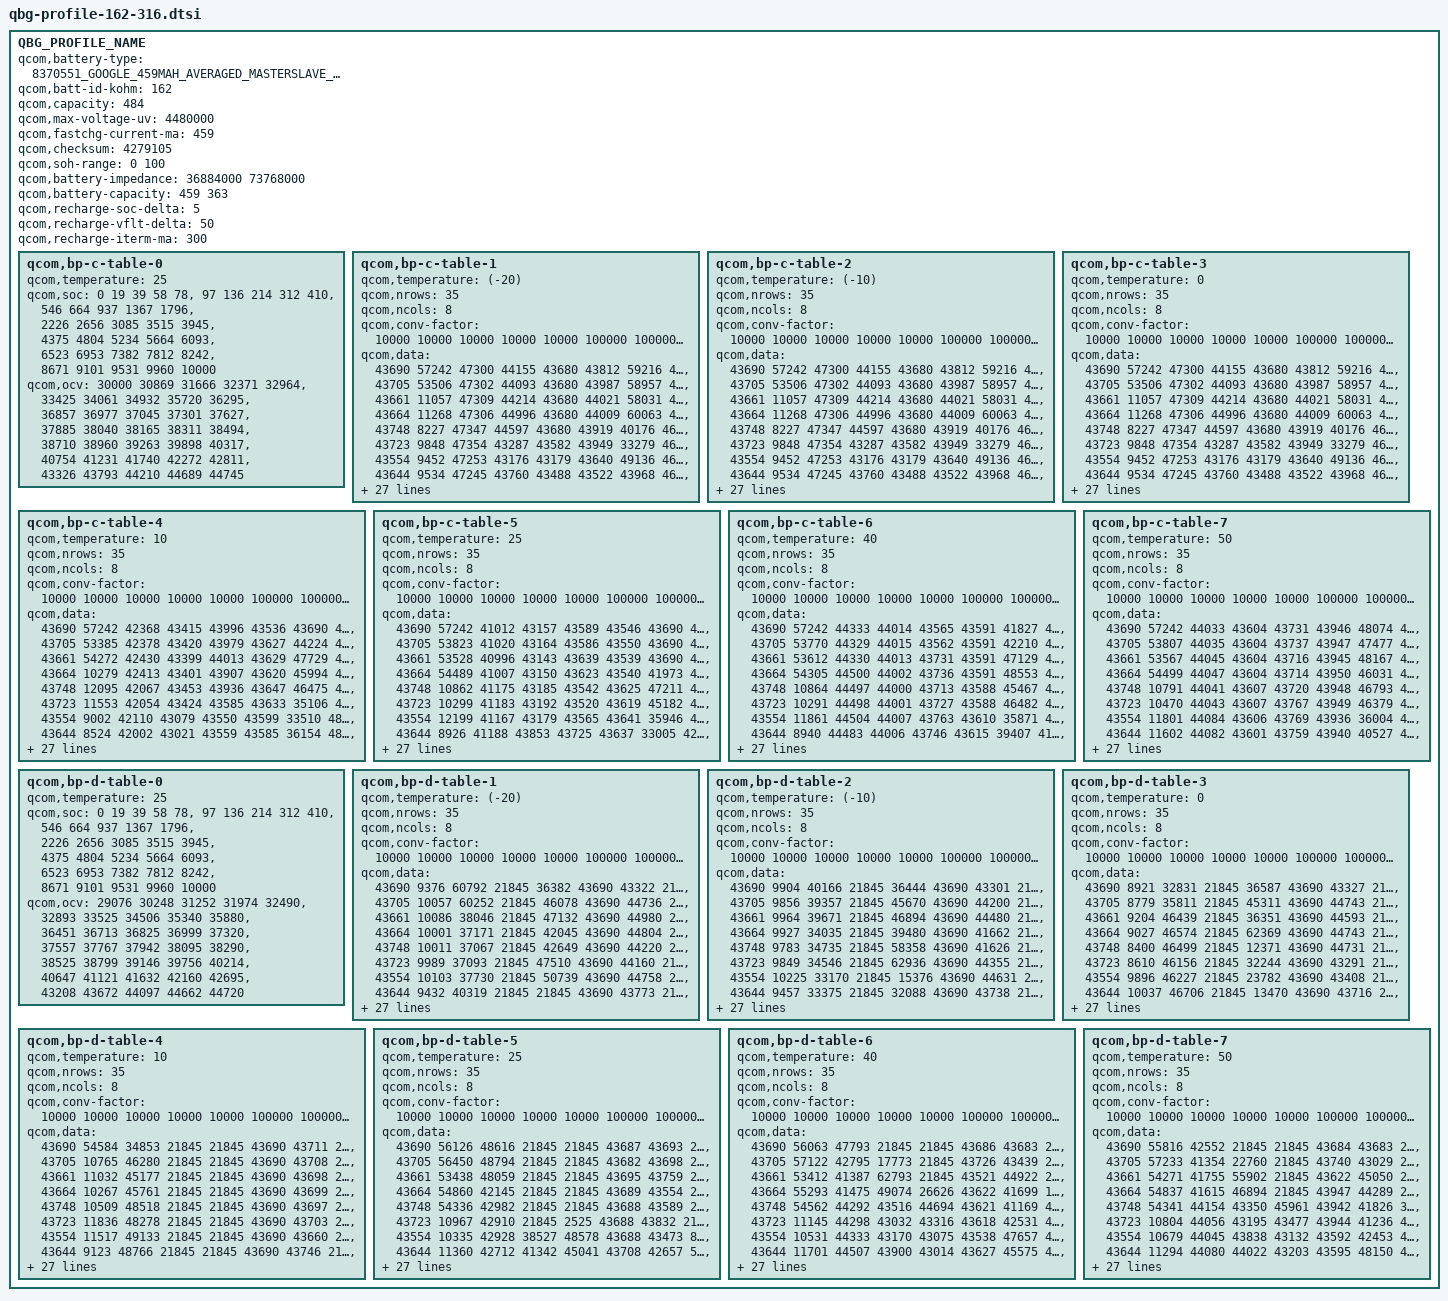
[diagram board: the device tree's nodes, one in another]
/*QBG Profiling Rev. 2.8*/

QBG_PROFILE_NAME {
	qcom,battery-type = "8370551_GOOGLE_459MAH_AVERAGED_MASTERSLAVE_MAR6TH2026";
	qcom,batt-id-kohm = <162>;
	qcom,capacity = <484>;
	qcom,max-voltage-uv = <4480000>;
	qcom,fastchg-current-ma = <459>;
	qcom,checksum = <4279105>; /*@5, 0.005V, 4% */
	qcom,soh-range = <0 100>;
	qcom,battery-impedance = <36884000 73768000>; /*Nominal_Impedance in 10nohm @ SOC 50% 25C* 0:fresh cell, 1: aged cell*/
	qcom,battery-capacity = <459 363>; /*Nominal_Capacity in mAh. 0: fresh cell, 1:aged cell*/ 
	qcom,recharge-soc-delta =<5>; /*SOC delta (in percent) dropped from EOC SOC to enable recharge*/ 
	qcom,recharge-vflt-delta =<50>; /*vfloat delta (in mV) dropped from regular vfloat in recharge*/ 
	qcom,recharge-iterm-ma = <300>; /*termination current (in mA) in recharge*/ 

	qcom,bp-c-table-0 {
		qcom,temperature = <25>;
		qcom,soc = <    0    19    39    58    78>,
			<   97   136   214   312   410>,
			<  546   664   937  1367  1796>,
			< 2226  2656  3085  3515  3945>,
			< 4375  4804  5234  5664  6093>,
			< 6523  6953  7382  7812  8242>,
			< 8671  9101  9531  9960 10000>;
		qcom,ocv = <30000 30869 31666 32371 32964>,
			<33425 34061 34932 35720 36295>,
			<36857 36977 37045 37301 37627>,
			<37885 38040 38165 38311 38494>,
			<38710 38960 39263 39898 40317>,
			<40754 41231 41740 42272 42811>,
			<43326 43793 44210 44689 44745>;
	};
	qcom,bp-c-table-1 {
		qcom,temperature = <(-20)>;
		qcom,nrows = <35>;
		qcom,ncols = <8>;
		qcom,conv-factor = <10000 10000 10000 10000 10000 100000 100000 10000>;
		qcom,data = <43690 57242 47300 44155 43680 43812 59216 46344>,
			<43705 53506 47302 44093 43680 43987 58957 46532>,
			<43661 11057 47309 44214 43680 44021 58031 46493>,
			<43664 11268 47306 44996 43680 44009 60063 46507>,
			<43748  8227 47347 44597 43680 43919 40176 46176>,
			<43723  9848 47354 43287 43582 43949 33279 46142>,
			<43554  9452 47253 43176 43179 43640 49136 46232>,
			<43644  9534 47245 43760 43488 43522 43968 46850>,
			<43922 15072 47295 43664 43497 43625 44008 47096>,
			<43824 14882 47233 43666 43417 43622 44002 47039>,
			<43144 14959 47283 43758 43398 43619 43977 47017>,
			<43058 14929 47355 43772 43406 43625 43816 47013>,
			<43267 15121 47286 43765 43402 43625 43838 47019>,
			<45053 14726 47130 43052 43306 43543 44303 46422>,
			<44462 16010 47109 44221 43917 43624 32951 35351>,
			<41496 15972 47254 44069 43836 43542 35658 35397>,
			<41162 16285 47235 44101 43843 43536 46584 35740>,
			<42663 16139 47334 44443 43191 43548 46957 35704>,
			<42769 15491 47359 44502 43250 43547 45395 34831>,
			<42435 15457 47124 44360 43062 43521 47103 35094>,
			<48061 15645 47168 41604 43018 43535 46985 36565>,
			<47214 13225 47492 41725 43046 43572 45995 36788>,
			<48856 12332 47407 41505 43041 43583 47247 36001>,
			<48266 14014 47429 41551 43110 43553 42769 36155>,
			<48487 14106 48682 41958 43394 43560 41041 33742>,
			<46033 13771 49025 41834 43269 43728 41551 33079>,
			<45443  2946 48915 41117 44789 43742 44321 33972>,
			<46716  2467 48185 40995 44998 43736 44172 39866>,
			<46126  3671 48445 41033 44101 43736 44941 40552>,
			<35480  3158 45747 41357 41916 43742 44744 37867>,
			<35701   601 45786 41450 42699 43743 43319 37962>,
			<35111   110 46016 41392 47936 43743 43099 60512>,
			<36753  1734 46079 41792 45451 43718 43235 64340>,
			<35906  1203 45903 44637 49003 43751 43945 57741>,
			<36282  1258 45909 44774 48678 43747 43639 58124>;
	};
	qcom,bp-c-table-2 {
		qcom,temperature = <(-10)>;
		qcom,nrows = <35>;
		qcom,ncols = <8>;
		qcom,conv-factor = <10000 10000 10000 10000 10000 100000 100000 10000>;
		qcom,data = <43690 57242 47300 44155 43680 43812 59216 46344>,
			<43705 53506 47302 44093 43680 43987 58957 46532>,
			<43661 11057 47309 44214 43680 44021 58031 46493>,
			<43664 11268 47306 44996 43680 44009 60063 46507>,
			<43748  8227 47347 44597 43680 43919 40176 46176>,
			<43723  9848 47354 43287 43582 43949 33279 46142>,
			<43554  9452 47253 43176 43179 43640 49136 46232>,
			<43644  9534 47245 43760 43488 43522 43968 46850>,
			<43922 15072 47295 43664 43497 43625 44008 47096>,
			<43824 14882 47233 43666 43417 43622 44002 47039>,
			<43144 14959 47283 43758 43398 43619 43977 47017>,
			<43058 14929 47355 43772 43406 43625 43816 47013>,
			<43267 15121 47286 43765 43402 43625 43838 47019>,
			<45053 14726 47130 43052 43306 43543 44303 46422>,
			<44462 16010 47109 44221 43917 43624 32951 35351>,
			<41496 15972 47254 44069 43836 43542 35658 35397>,
			<41162 16285 47235 44101 43843 43536 46584 35740>,
			<42663 16139 47334 44443 43191 43548 46957 35704>,
			<42769 15491 47359 44502 43250 43547 45395 34831>,
			<42435 15457 47124 44360 43062 43521 47103 35094>,
			<48061 15645 47168 41604 43018 43535 46985 36565>,
			<47214 13225 47492 41725 43046 43572 45995 36788>,
			<48856 12332 47407 41505 43041 43583 47247 36001>,
			<48266 14014 47429 41551 43110 43553 42769 36155>,
			<48487 14106 48682 41958 43394 43560 41041 33742>,
			<46033 13771 49025 41834 43269 43728 41551 33079>,
			<45443  2946 48915 41117 44789 43742 44321 33972>,
			<46716  2467 48185 40995 44998 43736 44172 39866>,
			<46126  3671 48445 41033 44101 43736 44941 40552>,
			<35480  3158 45747 41357 41916 43742 44744 37867>,
			<35701   601 45786 41450 42699 43743 43319 37962>,
			<35111   110 46016 41392 47936 43743 43099 60512>,
			<36753  1734 46079 41792 45451 43718 43235 64340>,
			<35906  1203 45903 44637 49003 43751 43945 57741>,
			<36282  1258 45909 44774 48678 43747 43639 58124>;
	};
	qcom,bp-c-table-3 {
		qcom,temperature = <0>;
		qcom,nrows = <35>;
		qcom,ncols = <8>;
		qcom,conv-factor = <10000 10000 10000 10000 10000 100000 100000 10000>;
		qcom,data = <43690 57242 47300 44155 43680 43812 59216 46344>,
			<43705 53506 47302 44093 43680 43987 58957 46532>,
			<43661 11057 47309 44214 43680 44021 58031 46493>,
			<43664 11268 47306 44996 43680 44009 60063 46507>,
			<43748  8227 47347 44597 43680 43919 40176 46176>,
			<43723  9848 47354 43287 43582 43949 33279 46142>,
			<43554  9452 47253 43176 43179 43640 49136 46232>,
			<43644  9534 47245 43760 43488 43522 43968 46850>,
			<43922 15072 47295 43664 43497 43625 44008 47096>,
			<43824 14882 47233 43666 43417 43622 44002 47039>,
			<43144 14959 47283 43758 43398 43619 43977 47017>,
			<43058 14929 47355 43772 43406 43625 43816 47013>,
			<43267 15121 47286 43765 43402 43625 43838 47019>,
			<45053 14726 47130 43052 43306 43543 44303 46422>,
			<44462 16010 47109 44221 43917 43624 32951 35351>,
			<41496 15972 47254 44069 43836 43542 35658 35397>,
			<41162 16285 47235 44101 43843 43536 46584 35740>,
			<42663 16139 47334 44443 43191 43548 46957 35704>,
			<42769 15491 47359 44502 43250 43547 45395 34831>,
			<42435 15457 47124 44360 43062 43521 47103 35094>,
			<48061 15645 47168 41604 43018 43535 46985 36565>,
			<47214 13225 47492 41725 43046 43572 45995 36788>,
			<48856 12332 47407 41505 43041 43583 47247 36001>,
			<48266 14014 47429 41551 43110 43553 42769 36155>,
			<48487 14106 48682 41958 43394 43560 41041 33742>,
			<46033 13771 49025 41834 43269 43728 41551 33079>,
			<45443  2946 48915 41117 44789 43742 44321 33972>,
			<46716  2467 48185 40995 44998 43736 44172 39866>,
			<46126  3671 48445 41033 44101 43736 44941 40552>,
			<35480  3158 45747 41357 41916 43742 44744 37867>,
			<35701   601 45786 41450 42699 43743 43319 37962>,
			<35111   110 46016 41392 47936 43743 43099 60512>,
			<36753  1734 46079 41792 45451 43718 43235 64340>,
			<35906  1203 45903 44637 49003 43751 43945 57741>,
			<36282  1258 45909 44774 48678 43747 43639 58124>;
	};
	qcom,bp-c-table-4 {
		qcom,temperature = <10>;
		qcom,nrows = <35>;
		qcom,ncols = <8>;
		qcom,conv-factor = <10000 10000 10000 10000 10000 100000 100000 10000>;
		qcom,data = <43690 57242 42368 43415 43996 43536 43690 48503>,
			<43705 53385 42378 43420 43979 43627 44224 48394>,
			<43661 54272 42430 43399 44013 43629 47729 48585>,
			<43664 10279 42413 43401 43907 43620 45994 48525>,
			<43748 12095 42067 43453 43936 43647 46475 48199>,
			<43723 11553 42054 43424 43585 43633 35106 48159>,
			<43554  9002 42110 43079 43550 43599 33510 48356>,
			<43644  8524 42002 43021 43559 43585 36154 48901>,
			<43922  9450 41991 43861 43639 43589 41303 49048>,
			<43824  9573 41986 43549 43186 44009 43897 48717>,
			<43144 15057 42040 43644 43842 44026 43860 48649>,
			<43058 14851 42017 43624 43179 43932 43855 48696>,
			<43267 15269 42196 43197 43629 43962 35366 48701>,
			<45053 14589 42185 43370 43529 43617 33970 49000>,
			<44462 14629 42156 44676 43608 43624 36055 48968>,
			<41496 16073 42764 44743 43913 43541 35063 49007>,
			<41162 15948 42948 44582 44009 43540 46518 48922>,
			<42663 16382 42994 44554 44020 43543 46609 48926>,
			<42769 16241 42983 44574 43990 43537 45075 48995>,
			<42435 15406 42986 44642 43825 43536 45292 48960>,
			<48061 15846 42907 44613 43781 43542 35736 48304>,
			<47214 13024 42929 44982 43789 43626 38912 48263>,
			<48856 12523 42885 44635 44017 43549 45157 49006>,
			<48266 13999 43000 44986 43996 43526 47678 48269>,
			<48487 14086 42814 45047 43801 43530 42899 48552>,
			<46033 13771 42871 44822 43863 43580 41382 45753>,
			<45443  2972 42127 44214 43255 43558 41873 46075>,
			<46716  2435 42026 44253 43127 43564 44397 45160>,
			<46126  3993 42054 44134 43324 43566 44092 46807>,
			<35480  3567 42439 44430 44559 43566 44927 46099>,
			<35701  1004 47783 44441 44244 43566 44550 35642>,
			<35111   441 47767 44428 41753 43553 43376 36637>,
			<36753  1543 47829 44034 48025 43552 43434 34571>,
			<35906  1220 47743 43321 42220 43743 43985 33671>,
			<36282  1086 48017 43395 42139 43735 44013 33353>;
	};
	qcom,bp-c-table-5 {
		qcom,temperature = <25>;
		qcom,nrows = <35>;
		qcom,ncols = <8>;
		qcom,conv-factor = <10000 10000 10000 10000 10000 100000 100000 10000>;
		qcom,data = <43690 57242 41012 43157 43589 43546 43690 42470>,
			<43705 53823 41020 43164 43586 43550 43690 42382>,
			<43661 53528 40996 43143 43639 43539 43690 42064>,
			<43664 54489 41007 43150 43623 43540 41973 42084>,
			<43748 10862 41175 43185 43542 43625 47211 41992>,
			<43723 10299 41183 43192 43520 43619 45182 42205>,
			<43554 12199 41167 43179 43565 43641 35946 42114>,
			<43644  8926 41188 43853 43725 43637 33005 42773>,
			<43922  8482 41107 43878 43722 43596 45496 42968>,
			<43824 10093 41091 43803 43765 43608 48508 42902>,
			<43144  9555 41141 43827 43773 43612 47422 42914>,
			<43058 15067 41131 43826 43751 43613 47451 42609>,
			<43267 14879 41797 43800 43772 43612 35761 42568>,
			<45053 15135 41851 43255 43522 43628 46764 42852>,
			<44462 14417 41736 43048 43596 43624 45184 42836>,
			<41496 14679 41942 43017 43608 43540 45945 42837>,
			<41162 15922 41983 43013 43606 43540 45988 42819>,
			<42663 16319 41884 43035 43941 43543 49004 42824>,
			<42769 16141 41867 43021 43933 43543 47788 42816>,
			<42435 15604 41893 43059 43992 43537 42883 42153>,
			<48061 15772 41559 43062 43829 43538 42995 42127>,
			<47214 12954 41542 43104 43781 43539 48783 42235>,
			<48856 13301 41547 43453 43811 43619 33191 42201>,
			<48266 12656 41587 43069 43957 43542 41413 42962>,
			<48487 14295 41568 43010 43929 43538 41127 42808>,
			<46033 13720 41568 43118 44002 43544 41558 42850>,
			<45443  2981 41594 43435 43992 43523 44408 42219>,
			<46716  2470 41587 43500 43801 43531 44145 42097>,
			<46126  3978 41541 43296 43168 43575 44271 42302>,
			<35480  3473 41910 43389 43223 43573 44210 47661>,
			<35701   916 41979 44715 43408 43532 44905 47892>,
			<35111   443 41768 43353 44663 43520 44595 47406>,
			<36753  1560 41758 43304 44934 43521 44815 47421>,
			<35906  1083 41756 43259 41717 43528 43167 48962>,
			<36282  1123 41786 43171 44539 43640 43829 48867>;
	};
	qcom,bp-c-table-6 {
		qcom,temperature = <40>;
		qcom,nrows = <35>;
		qcom,ncols = <8>;
		qcom,conv-factor = <10000 10000 10000 10000 10000 100000 100000 10000>;
		qcom,data = <43690 57242 44333 44014 43565 43591 41827 41838>,
			<43705 53770 44329 44015 43562 43591 42210 41834>,
			<43661 53612 44330 44013 43731 43591 47129 41750>,
			<43664 54305 44500 44002 43736 43591 48553 41746>,
			<43748 10864 44497 44000 43713 43588 45467 41753>,
			<43723 10291 44498 44001 43727 43588 46482 41732>,
			<43554 11861 44504 44007 43763 43610 35871 41742>,
			<43644  8940 44483 44006 43746 43615 39407 41761>,
			<43922  8597 44533 44008 43669 43605 40395 41933>,
			<43824 10192 44541 43908 43755 43939 34961 41953>,
			<43144  9578 44539 43605 43768 43952 47415 41865>,
			<43058 15091 44512 43946 43664 43960 34996 41903>,
			<43267 14906 44526 43941 43764 43967 45741 41886>,
			<45053 15327 44432 44002 43551 43613 42065 41827>,
			<44462 14355 44423 43983 43594 43615 47783 41122>,
			<41496 14599 44469 43823 43639 43610 45578 41148>,
			<41162 16078 44475 43990 43622 43591 48152 41823>,
			<42663 15953 44459 43810 43616 43584 47608 41818>,
			<42769 16177 44121 43814 43584 43591 42181 41146>,
			<42435 15600 44099 44023 44029 43615 41647 41111>,
			<48061 15760 44107 43933 43783 43615 44141 41158>,
			<47214 12947 44146 44021 43805 43585 41189 40997>,
			<48856 13271 44153 43787 43987 43586 47123 41008>,
			<48266 12644 44154 43970 43593 43589 41769 41833>,
			<48487 14279 44135 43991 43598 43587 41965 41842>,
			<46033 13708 44135 43827 43612 43594 41709 41126>,
			<45443  2991 44132 43798 43940 43644 44344 41208>,
			<46716  2477 44155 43850 43910 43623 44102 41013>,
			<46126  4022 44158 43138 43976 43626 44066 41356>,
			<35480  3474 44145 43213 43807 43542 44278 41315>,
			<35701   914 44099 43222 43143 43626 44201 42701>,
			<35111   429 44115 43220 43437 43618 45003 42978>,
			<36753  1544 44455 43896 43179 43632 41689 41278>,
			<35906  1034 44116 43902 44767 43599 43501 42844>,
			<36282  1138 44142 43994 45013 43955 43162 42194>;
	};
	qcom,bp-c-table-7 {
		qcom,temperature = <50>;
		qcom,nrows = <35>;
		qcom,ncols = <8>;
		qcom,conv-factor = <10000 10000 10000 10000 10000 100000 100000 10000>;
		qcom,data = <43690 57242 44033 43604 43731 43946 48074 41685>,
			<43705 53807 44035 43604 43737 43947 47477 41687>,
			<43661 53567 44045 43604 43716 43945 48167 41683>,
			<43664 54499 44047 43604 43714 43950 46031 41692>,
			<43748 10791 44041 43607 43720 43948 46793 41689>,
			<43723 10470 44043 43607 43767 43949 46379 41669>,
			<43554 11801 44084 43606 43769 43936 36004 41677>,
			<43644 11602 44082 43601 43759 43940 40527 41724>,
			<43922  8260 44088 43603 43664 43967 38276 41620>,
			<43824 10125 44068 43611 43679 43956 40716 41600>,
			<43144  9688 44064 43621 43669 43925 46928 41634>,
			<43058 14991 44077 43520 43664 44003 45388 44400>,
			<43267 15093 44078 43548 43720 44002 42261 41637>,
			<45053 15263 44245 43610 43520 43907 42572 41532>,
			<44462 14545 44240 43950 43629 43906 42185 41581>,
			<41496 14810 44249 43951 43593 43916 47622 41590>,
			<41162 16017 44225 43605 43629 43912 47718 41503>,
			<42663 15949 44232 43937 43550 43967 47838 41476>,
			<42769 16165 44275 43928 43542 43961 42082 41586>,
			<42435 15608 44283 43963 43915 43904 41489 41914>,
			<48061 15763 44257 43548 43785 43933 44637 41874>,
			<47214 12949 44268 43638 43791 43915 41646 41978>,
			<48856 13117 44265 43943 44021 43954 42897 41954>,
			<48266 12667 44267 43588 43631 43913 41616 41518>,
			<48487 14277 44266 43944 43541 43954 41695 41532>,
			<46033 13697 44181 43913 43617 43939 44375 41568>,
			<45443  2981 44181 43924 43591 43600 44145 41892>,
			<46716  2490 44264 43992 43603 43590 44333 41969>,
			<46126  3980 44265 43800 43965 43633 44500 41839>,
			<35480  3479 44268 43901 44020 43645 44142 41104>,
			<35701   926 44257 43856 43794 43633 44063 40988>,
			<35111    81 44283 43174 43235 43598 44053 41456>,
			<36753  1585 44273 44006 43972 43937 41595 41754>,
			<35906  1038 44274 44012 44571 43606 43325 42915>,
			<36282  1143 44873 43970 44785 43923 43114 42738>;
	};
	qcom,bp-d-table-0 {
		qcom,temperature = <25>;
		qcom,soc = <    0    19    39    58    78>,
			<   97   136   214   312   410>,
			<  546   664   937  1367  1796>,
			< 2226  2656  3085  3515  3945>,
			< 4375  4804  5234  5664  6093>,
			< 6523  6953  7382  7812  8242>,
			< 8671  9101  9531  9960 10000>;
		qcom,ocv = <29076 30248 31252 31974 32490>,
			<32893 33525 34506 35340 35880>,
			<36451 36713 36825 36999 37320>,
			<37557 37767 37942 38095 38290>,
			<38525 38799 39146 39756 40214>,
			<40647 41121 41632 42160 42695>,
			<43208 43672 44097 44662 44720>;
	};
	qcom,bp-d-table-1 {
		qcom,temperature = <(-20)>;
		qcom,nrows = <35>;
		qcom,ncols = <8>;
		qcom,conv-factor = <10000 10000 10000 10000 10000 100000 100000 10000>;
		qcom,data = <43690  9376 60792 21845 36382 43690 43322 21845>,
			<43705 10057 60252 21845 46078 43690 44736 21845>,
			<43661 10086 38046 21845 47132 43690 44980 21845>,
			<43664 10001 37171 21845 42045 43690 44804 21845>,
			<43748 10011 37067 21845 42649 43690 44220 21845>,
			<43723  9989 37093 21845 47510 43690 44160 21845>,
			<43554 10103 37730 21845 50739 43690 44758 21845>,
			<43644  9432 40319 21845 21845 43690 43773 21845>,
			<43922  9236 39981 21845   571 43690 43717 21845>,
			<43824  9306 40926 21845 50040 43690 43563 21845>,
			<43144  9709 40657 21845 38335 43690 43546 21845>,
			<43058  9526 39061 21845 33557 43690 43966 21845>,
			<43267 14998 34242 29340 48281 43691 43171 21845>,
			<45053 15273 34375 56637 48339 43691 43421 21845>,
			<44462 15115 33364 57941 47912 43688 43282 21127>,
			<41496 14485 36234 39071 42935 43689 44741 26837>,
			<41162 14452 36840 36410 41842 43694 44943 13624>,
			<42663 14638 34832 46749 44313 43692 44906 11536>,
			<42769 16030 35592 48183 44256 43682 44185 56567>,
			<42435 15966 35374 47302 44844 43680 44270 50048>,
			<48061 16234 46442 47752 45051 43681 44194 51223>,
			<47214 15375 46437 42096 44983 43684 44261 51959>,
			<48856 15633 46445 42029 44649 43706 44288 62881>,
			<48266 13234 46458 42233 44573 43710 41742 62669>,
			<48487 12384 46454 42841 44985 43657 42748 62716>,
			<46033 13922 46444 42791 45007 43774 47256 62885>,
			<45443 13732 46385 42863 44206 43552 45714 51912>,
			<46716  2962 35575 42222 44058 43552 48531 52192>,
			<46126  2508 46433 42060 44441 43554 48375 51337>,
			<35480  3896 46392 42456 44322 43566 49041 51281>,
			<35701  3383 46398 42316 44334 43735 47210 51693>,
			<35111   801 46543 47762 44135 43716 42128 51585>,
			<36753   304 46394 47842 45020 43677 41624 51355>,
			<35906  1238 46400 47783 43387 43690 43612 52207>,
			<36282  1123 46425 47785 43271 43690 43756 52116>;
	};
	qcom,bp-d-table-2 {
		qcom,temperature = <(-10)>;
		qcom,nrows = <35>;
		qcom,ncols = <8>;
		qcom,conv-factor = <10000 10000 10000 10000 10000 100000 100000 10000>;
		qcom,data = <43690  9904 40166 21845 36444 43690 43301 21845>,
			<43705  9856 39357 21845 45670 43690 44200 21845>,
			<43661  9964 39671 21845 46894 43690 44480 21845>,
			<43664  9927 34035 21845 39480 43690 41662 21845>,
			<43748  9783 34735 21845 58358 43690 41626 21845>,
			<43723  9849 34546 21845 62936 43690 44355 21845>,
			<43554 10225 33170 21845 15376 43690 44631 21845>,
			<43644  9457 33375 21845 32088 43690 43738 21845>,
			<43922  9326 36148 21845 64674 43690 43533 21845>,
			<43824  9609 36254 21845 32858 43690 43946 21845>,
			<43144  9533 36736 21845 48689 43690 43803 21845>,
			<43058  9567 35203 12394 42605 43691 43069 21845>,
			<43267 14848 46355 33660 44228 43688 44971  6457>,
			<45053 15298 45359 49068 44923 43695 44053 50303>,
			<44462 15185 45875 42000 44795 43681 41661 65141>,
			<41496 14371 45949 42653 43389 43705 41644 59239>,
			<41162 14768 46035 41136 43471 43651 44395 58349>,
			<42663 14617 45832 41487 43070 43742 41855 61272>,
			<42769 16117 45875 41707 43203 43735 41180 59687>,
			<42435 16267 45840 44368 43225 43560 41211 60250>,
			<48061 15512 45843 41677 43230 43554 47306 60352>,
			<47214 15656 45941 41500 43030 43578 48504 60358>,
			<48856 12893 45936 41549 43505 43583 45747 60223>,
			<48266 12351 45931 41880 43334 43580 48227 60260>,
			<48487 14028 45878 41764 44578 43581 49096 59580>,
			<46033 13516 45860 41130 44934 43581 48807 59518>,
			<45443  2783 45826 41001 44850 43577 47161 59848>,
			<46716  2105 45827 41379 44868 43556 47883 61103>,
			<46126  3584 45834 41424 44173 43554 47679 60946>,
			<35480  3079 45885 41322 44167 43561 42491 61372>,
			<35701   548 45873 41284 44203 43732 42131 61313>,
			<35111   226 45826 41303 45024 43731 42935 61365>,
			<36753   351 45869 41392 43362 43712 41833 61153>,
			<35906  1058 46050 41124 43844 43763 44927 59693>,
			<36282  1124 46059 41813 43887 43773 44832 59689>;
	};
	qcom,bp-d-table-3 {
		qcom,temperature = <0>;
		qcom,nrows = <35>;
		qcom,ncols = <8>;
		qcom,conv-factor = <10000 10000 10000 10000 10000 100000 100000 10000>;
		qcom,data = <43690  8921 32831 21845 36587 43690 43327 21845>,
			<43705  8779 35811 21845 45311 43690 44743 21845>,
			<43661  9204 46439 21845 36351 43690 44593 21845>,
			<43664  9027 46574 21845 62369 43690 44743 21845>,
			<43748  8400 46499 21845 12371 43690 44731 21845>,
			<43723  8610 46156 21845 32244 43690 43291 21845>,
			<43554  9896 46227 21845 23782 43690 43408 21845>,
			<43644 10037 46706 21845 13470 43690 43716 21845>,
			<43922  9260 46847 21845 39140 43690 43635 21845>,
			<43824  9301 45300 21845 48802 43690 43995 21845>,
			<43144  9690 45648 57164 44337 43691 43091 21845>,
			<43058  9489 45701 33582 44970 43691 43341  6771>,
			<43267 15100 48912 41609 43392 43682 44864 59351>,
			<45053 15261 49087 44127 43138 43679 41403 37100>,
			<44462 14575 48836 44044 43247 43560 45178 39177>,
			<41496 14761 48682 44248 43055 43556 46599 39581>,
			<41162 14812 48849 44210 43137 43576 49092 34710>,
			<42663 14686 48683 44926 43841 43577 47661 33180>,
			<42769 15924 48753 44919 43885 43570 47206 32930>,
			<42435 16174 48673 44871 43845 43569 48922 33748>,
			<48061 15418 48673 44881 43165 43575 49060 33691>,
			<47214 15725 48686 44214 43049 43573 48825 33666>,
			<48856 13212 48835 44277 43087 43531 47430 33778>,
			<48266 12401 48841 44084 43464 43531 47295 33551>,
			<48487 13929 48868 44462 43347 43573 48011 33003>,
			<46033 13415 48875 44484 44754 43574 42257 32847>,
			<45443  2684 48786 44395 44563 43581 42817 33223>,
			<46716  2173 48893 44362 44562 43578 41238 33067>,
			<46126  3697 48891 44378 44559 43552 41105 33080>,
			<35480  3188 48791 41644 44752 43565 41146 33052>,
			<35701   611 48787 41663 44694 43565 40963 33113>,
			<35111    44 48876 41645 43383 43564 41420 34433>,
			<36753  1664 48785 44342 43085 43567 42730 33099>,
			<35906  1067 48827 44443 43792 43561 42939 33209>,
			<36282  1044 48801 44423 43787 43561 42890 32850>;
	};
	qcom,bp-d-table-4 {
		qcom,temperature = <10>;
		qcom,nrows = <35>;
		qcom,ncols = <8>;
		qcom,conv-factor = <10000 10000 10000 10000 10000 100000 100000 10000>;
		qcom,data = <43690 54584 34853 21845 21845 43690 43711 21845>,
			<43705 10765 46280 21845 21845 43690 43708 21845>,
			<43661 11032 45177 21845 21845 43690 43698 21845>,
			<43664 10267 45761 21845 21845 43690 43699 21845>,
			<43748 10509 48518 21845 21845 43690 43697 21845>,
			<43723 11836 48278 21845 21845 43690 43703 21845>,
			<43554 11517 49133 21845 21845 43690 43660 21845>,
			<43644  9123 48766 21845 21845 43690 43746 21845>,
			<43922  8491 47454 21845 59168 43690 43547 21845>,
			<43824 10183 47135 21845 48778 43690 43846 21845>,
			<43144  9282 47883 38428 44884 43691 44644 27185>,
			<43058  9713 48098 47858 43446 43689 44479 50407>,
			<43267  9576 47664 44574 44031 43746 41324 34478>,
			<45053 14946 47824 43347 43995 43718 41996 35408>,
			<44462 14522 42354 44764 43141 43579 47300 46585>,
			<41496 14415 42276 44739 43261 43575 47304 47084>,
			<41162 14787 42454 44779 43181 43528 47929 45347>,
			<42663 14685 42437 44693 43883 43534 47406 45066>,
			<42769 15876 42439 44779 43884 43535 48643 45200>,
			<42435 16172 42282 44693 43848 43535 47410 45910>,
			<48061 15571 42275 44783 43866 43533 48114 45932>,
			<47214 15670 42487 44793 43173 43533 42310 45839>,
			<48856 13227 42471 44765 43260 43522 42444 45938>,
			<48266 12308 42373 44565 43121 43522 42296 45269>,
			<48487 13918 42416 45017 43362 43550 48800 46761>,
			<46033 13377 42407 44810 44735 43520 42342 46810>,
			<45443  2661 42403 44861 44709 43572 41390 46810>,
			<46716  2156 42428 44863 43381 43570 41584 46798>,
			<46126  3705 42379 44824 43311 43580 41586 46789>,
			<35480  3151 42368 44897 43493 43582 41768 46607>,
			<35701   624 42491 44804 43413 43576 41834 46667>,
			<35111    11 42463 44837 43448 43580 40982 47029>,
			<36753  1773 42461 45050 43047 43571 41286 47026>,
			<35906  1058 42464 44970 43853 43568 42983 46686>,
			<36282  1134 42472 44627 43888 43568 42948 46660>;
	};
	qcom,bp-d-table-5 {
		qcom,temperature = <25>;
		qcom,nrows = <35>;
		qcom,ncols = <8>;
		qcom,conv-factor = <10000 10000 10000 10000 10000 100000 100000 10000>;
		qcom,data = <43690 56126 48616 21845 21845 43687 43693 21845>,
			<43705 56450 48794 21845 21845 43682 43698 21845>,
			<43661 53438 48059 21845 21845 43695 43759 21845>,
			<43664 54860 42145 21845 21845 43689 43554 21845>,
			<43748 54336 42982 21845 21845 43688 43589 21845>,
			<43723 10967 42910 21845  2525 43688 43832 21845>,
			<43554 10335 42928 38527 48578 43688 43473  8155>,
			<43644 11360 42712 41342 45041 43708 42657 57393>,
			<43922  8358 42681 44752 43445 43772 45153 46118>,
			<43824  9858 41270 43292 43263 43739 45531 48555>,
			<43144  9417 41385 43447 43811 43552 48781 47115>,
			<43058  9667 41081 43089 43973 43580 42568 48080>,
			<43267  9587 41168 43261 43640 43532 42277 42477>,
			<45053 14893 41198 43142 43542 43538 48878 42194>,
			<44462 15202 41821 43237 44027 43550 42555 42092>,
			<41496 14367 41834 43250 43832 43539 42155 42089>,
			<41162 14637 41728 43222 43853 43540 47970 42401>,
			<42663 16028 41783 43218 43182 43541 47985 42428>,
			<42769 15973 41786 43260 43891 43540 42517 41999>,
			<42435 16184 41942 43263 43825 43540 42662 42234>,
			<48061 15575 41921 43208 43994 43541 42927 42161>,
			<47214 15653 41971 43259 43970 43541 41257 42842>,
			<48856 12864 41966 43200 43811 43543 42555 42162>,
			<48266 12774 41861 43420 43451 43593 47073 47812>,
			<48487 14268 41907 43429 43457 43618 47760 47659>,
			<46033 13421 41895 43075 43417 43550 41532 47798>,
			<45443  2571 41901 43436 43019 43549 44355 42242>,
			<46716  2058 41888 43418 43194 43538 41715 42490>,
			<46126  3610 41916 43415 43784 43551 41787 42414>,
			<35480  3181 41865 43421 43992 43545 41025 42104>,
			<35701   610 41877 43093 43993 43547 41038 42090>,
			<35111    50 41928 43110 43823 43546 41162 42007>,
			<36753  1771 41774 43015 43818 43548 41004 42091>,
			<35906  1244 41740 43021 43982 43627 41447 42093>,
			<36282  1050 41731 43010 44021 43627 41409 42093>;
	};
	qcom,bp-d-table-6 {
		qcom,temperature = <40>;
		qcom,nrows = <35>;
		qcom,ncols = <8>;
		qcom,conv-factor = <10000 10000 10000 10000 10000 100000 100000 10000>;
		qcom,data = <43690 56063 47793 21845 21845 43686 43683 21845>,
			<43705 57122 42795 17773 21845 43726 43439 21845>,
			<43661 53412 41387 62793 21845 43521 44922 21845>,
			<43664 55293 41475 49074 26626 43622 41699 18874>,
			<43748 54562 44292 43516 44694 43621 41169 47810>,
			<43723 11145 44298 43032 43316 43618 42531 42053>,
			<43554 10531 44333 43170 43075 43538 47657 43001>,
			<43644 11701 44507 43900 43014 43627 45575 42515>,
			<43922  8334 44533 43880 43075 43619 46483 42594>,
			<43824  9900 44536 43781 43161 43623 35478 41295>,
			<43144  9371 44524 43778 43941 43646 35553 40960>,
			<43058  9671 44520 43890 43638 43620 47864 40975>,
			<43267  9538 44434 43996 43573 43637 47604 41818>,
			<45053 15055 44420 43957 43528 43606 42420 41943>,
			<44462 15112 44478 44029 43600 43612 42590 41814>,
			<41496 14383 44461 44012 43961 43600 42903 41822>,
			<41162 14813 44457 44030 43779 43946 42716 41021>,
			<42663 16103 44119 43819 43849 43942 41336 41025>,
			<42769 15953 44126 43815 43800 43940 42722 41059>,
			<42435 16151 44102 43990 43997 43951 41268 41178>,
			<48061 15368 44111 43822 43913 43947 42803 41142>,
			<47214 15623 44151 43979 43936 43601 42628 41844>,
			<48856 13217 44146 43971 44011 43602 42512 41136>,
			<48266 12774 44133 43801 43072 43609 42736 42684>,
			<48487 14255 44129 43852 43036 43602 41602 42682>,
			<46033 13330 44130 43206 43797 43948 41125 41221>,
			<45443  2616 44141 43216 44008 43588 41055 41448>,
			<46716  2106 44131 43263 43948 43623 42683 41039>,
			<46126  3593 44135 43163 43638 43616 42001 41011>,
			<35480  3090 44158 43861 43621 43620 42248 41207>,
			<35701   530 44149 43896 43620 43647 42268 41113>,
			<35111    34 44102 43788 43638 43599 42012 41137>,
			<36753  1688 44114 43818 43612 43588 42884 41145>,
			<35906  1264 44456 43977 43967 43610 41460 41143>,
			<36282  1080 44457 43979 43965 43589 41373 41098>;
	};
	qcom,bp-d-table-7 {
		qcom,temperature = <50>;
		qcom,nrows = <35>;
		qcom,ncols = <8>;
		qcom,conv-factor = <10000 10000 10000 10000 10000 100000 100000 10000>;
		qcom,data = <43690 55816 42552 21845 21845 43684 43683 21845>,
			<43705 57233 41354 22760 21845 43740 43029 21845>,
			<43661 54271 41755 55902 21845 43622 45050 21845>,
			<43664 54837 41615 46894 21845 43947 44289 21845>,
			<43748 54341 44154 43350 45961 43942 41826 36425>,
			<43723 10804 44056 43195 43477 43944 41236 42927>,
			<43554 10679 44045 43838 43132 43592 42453 41322>,
			<43644 11294 44080 44022 43203 43595 48150 41041>,
			<43922  9061 44070 44012 43071 43587 46906 41385>,
			<43824  8568 44079 44011 43249 43589 35838 40988>,
			<43144 10060 44246 43932 43937 43612 35357 41952>,
			<43058  9619 44242 43995 43526 43596 48572 41856>,
			<43267  9582 44252 43918 43555 43605 47975 41498>,
			<45053 14995 44229 43639 43560 43932 47131 41696>,
			<44462 15315 44234 43954 43540 43931 48016 41503>,
			<41496 14578 44275 43615 43595 43933 42104 41478>,
			<41162 14833 44285 43945 43975 44012 42655 41962>,
			<42663 16124 44281 43926 43799 44007 41025 41825>,
			<42769 16318 44260 43977 43834 44026 41287 41837>,
			<42435 16251 44258 43974 43959 44028 42794 41977>,
			<48061 15385 44270 43923 43590 43935 42964 41542>,
			<47214 15720 44266 43914 43618 43909 47769 41479>,
			<48856 13237 44182 43914 43945 43904 42478 41551>,
			<48266 12774 44179 44029 43228 43917 41892 40975>,
			<48487 14249 44178 43137 43836 44004 41465 41023>,
			<46033 13331 44177 43155 43955 43964 42746 41108>,
			<45443  2621 44177 43185 43633 43599 42045 41800>,
			<46716  2110 44182 43858 43520 43637 47499 41765>,
			<46126  3598 44180 43798 43528 43594 47164 41965>,
			<35480  3100 44264 43995 43524 43584 42151 41889>,
			<35701   536 44258 44001 43526 43601 42183 41546>,
			<35111    40 44260 43935 43526 43943 47635 41580>,
			<36753  1671 44286 43913 43625 43914 47631 41571>,
			<35906  1275 44278 43962 43592 43934 42729 41538>,
			<36282  1058 44279 43941 43598 43932 41438 41543>;
	};
};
